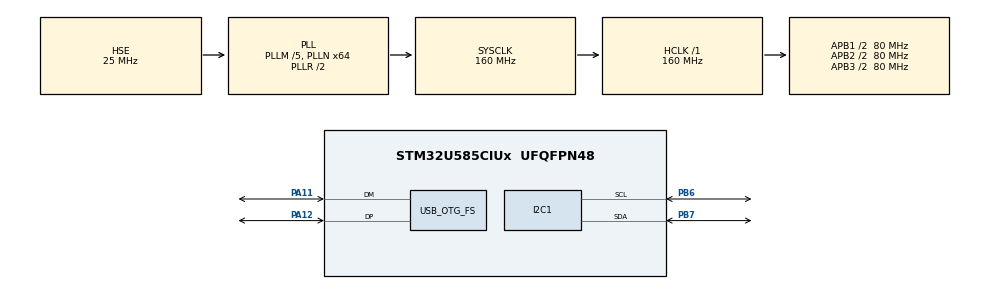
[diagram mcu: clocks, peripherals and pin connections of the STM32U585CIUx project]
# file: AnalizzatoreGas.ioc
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CORTEX_M33_NS.userName=CORTEX_M33
I2C1.Timing=0x10909CEC
Mcu.Family=STM32U5
Mcu.Name=STM32U585CIUx
Mcu.Package=UFQFPN48
NVIC.OTG_FS_IRQn=true\:0\:0\:false\:false\:true\:false\:true\:true\:true
NVIC.PriorityGroup=NVIC_PRIORITYGROUP_4
NVIC.TIM1_UP_IRQn=true\:15\:0\:false\:false\:true\:false\:false\:true\:true
NVIC.TimeBase=TIM1_UP_IRQn
NVIC.TimeBaseIP=TIM1
PA11.Mode=Device_Only
PA11.Signal=USB_OTG_FS_DM
PA12.Mode=Device_Only
PA12.Signal=USB_OTG_FS_DP
PA13\ (JTMS/SWDIO).Mode=Serial_Wire
PA13\ (JTMS/SWDIO).Signal=DEBUG_JTMS-SWDIO
PA14\ (JTCK/SWCLK).Mode=Serial_Wire
PA14\ (JTCK/SWCLK).Signal=DEBUG_JTCK-SWCLK
PB6.Mode=I2C
PB6.Signal=I2C1_SCL
PB7.Mode=I2C
PB7.Signal=I2C1_SDA
PH0-OSC_IN\ (PH0).Mode=HSE-External-Oscillator
PH0-OSC_IN\ (PH0).Signal=RCC_OSC_IN
PH1-OSC_OUT\ (PH1).Mode=HSE-External-Oscillator
PH1-OSC_OUT\ (PH1).Signal=RCC_OSC_OUT
ProjectManager.HeapSize=0x200
ProjectManager.StackSize=0x400
ProjectManager.TargetToolchain=STM32CubeIDE
RCC.ADCFreq_Value=16000000
RCC.AHBFreq_Value=160000000
RCC.APB1CLKDivider=RCC_HCLK_DIV2
RCC.APB1Freq_Value=80000000
RCC.APB1TimFreq_Value=160000000
RCC.APB2CLKDivider=RCC_HCLK_DIV2
RCC.APB2Freq_Value=80000000
RCC.APB2TimFreq_Value=160000000
RCC.APB3CLKDivider=RCC_HCLK_DIV2
RCC.APB3Freq_Value=80000000
RCC.CortexFreq_Value=160000000
RCC.EPOD_VALUE=25000000
RCC.HCLKFreq_Value=160000000
RCC.HSE_VALUE=25000000
RCC.HSI48_VALUE=48000000
RCC.HSI_VALUE=16000000
RCC.LSE_VALUE=32768
RCC.LSIDIV_VALUE=32000
RCC.MSI_VALUE=4000000
RCC.PLLM=5
RCC.PLLN=64
RCC.PLLSourceVirtual=RCC_PLLSOURCE_HSE
RCC.SYSCLKFreq_VALUE=160000000
RCC.SYSCLKSource=RCC_SYSCLKSOURCE_PLLCLK
RCC.USBFreq_Value=48000000
RCC.VCOOutputFreq_Value=320000000
THREADX.TX_APP_CREATION=1
THREADX.TX_APP_GENERATE_INIT_CODE=true
THREADX.TX_APP_MEM_POOL_SIZE=16384
THREADX.TX_APP_STACK_SIZE=4096
THREADX.TX_MINIMUM_STACK=1024
THREADX.TX_TIMER_THREAD_STACK_SIZE=2048
THREADX.TX_TIMER_TICKS_PER_SECOND=1000
USBX.Core_System=1
USBX.USBD_CDCACM_EPIN_ADDR=2
USBX.USBD_CDCACM_EPOUT_ADDR=3
USBX.USBX_DEVICE_APP_THREAD_Size=4096
USBX.USBX_DEVICE_SYS_SIZE=1024
USBX.UX_DEVICE_APP_MEM_POOL_SIZE=32768
USBX.UX_DEVICE_CDC_ACM=1
USBX.UX_Device_CoreStack=1
USB_OTG_FS.VirtualMode=Device_Only
VP_ICACHE_VS_ICACHE.Mode=DirectMappedCache
VP_LPBAMQUEUE_VS_QUEUE.Mode=QUEUEMODE
VP_LPBAM_VS_SIG1.Mode=SmartRun
VP_LPBAM_VS_SIG4.Mode=LPDMA1
VP_MEMORYMAP_VS_MEMORYMAP.Mode=CurAppReg
VP_PWR_VS_SECSignals.Mode=Security/Privilege
VP_SYS_VS_tim1.Mode=TIM1
VP_THREADX_VS_RTOSJjThreadXJjCoreJjDefault.Mode=Core_Default
VP_USBX_Core_System.Mode=Core_System
VP_USBX_UX\ Device\ CDC\ ACM\ Class_FS.Mode=UX_Device_class_CDC_ACM_FS
VP_USBX_UX\ Device\ CoreStack_FS.Mode=UX_Device_CoreStack_FS
board=custom

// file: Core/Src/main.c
/* USER CODE BEGIN Header */
/**
  ******************************************************************************
  * @file           : main.c
  * @brief          : Main program body
  ******************************************************************************
  * @attention
  *
  * Copyright (c) 2026 STMicroelectronics.
  * All rights reserved.
  *
  * This software is licensed under terms that can be found in the LICENSE file
  * in the root directory of this software component.
  * If no LICENSE file comes with this software, it is provided AS-IS.
  *
  ******************************************************************************
  */
/* USER CODE END Header */
#include "app_threadx.h"
#include "main.h"

I2C_HandleTypeDef hi2c1;

//PCD_HandleTypeDef hpcd_USB_OTG_FS;

void SystemClock_Config(void);
static void MX_GPIO_Init(void);
static void MX_ICACHE_Init(void);
static void MX_USB_OTG_FS_PCD_Init(void);
static void MX_I2C1_Init(void);

/* USER CODE BEGIN 0 */
PCD_HandleTypeDef hpcd_USB_OTG_FS;
/* USER CODE END 0 */

int main(void)
{

  /* MCU Configuration--------------------------------------------------------*/

  /* Reset of all peripherals, Initializes the Flash interface and the Systick. */
  HAL_Init();

  /* Configure the system clock */
  SystemClock_Config();

  /* Initialize all configured peripherals */
  MX_GPIO_Init();
  MX_ICACHE_Init();
  MX_USB_OTG_FS_PCD_Init();
  MX_I2C1_Init();

  MX_ThreadX_Init();

  /* We should never get here as control is now taken by the scheduler */

  /* Infinite loop */
  while (1)
  {

  }
}

void SystemClock_Config(void)
{
  RCC_OscInitTypeDef RCC_OscInitStruct = {0};
  RCC_ClkInitTypeDef RCC_ClkInitStruct = {0};

  /** Configure the main internal regulator output voltage
  */
  if (HAL_PWREx_ControlVoltageScaling(PWR_REGULATOR_VOLTAGE_SCALE1) != HAL_OK)
  {
    Error_Handler();
  }

  /** Initializes the CPU, AHB and APB buses clocks
  */
  RCC_OscInitStruct.OscillatorType = RCC_OSCILLATORTYPE_HSI48|RCC_OSCILLATORTYPE_HSE;
  RCC_OscInitStruct.HSEState = RCC_HSE_ON;
  RCC_OscInitStruct.HSI48State = RCC_HSI48_ON;
  RCC_OscInitStruct.PLL.PLLState = RCC_PLL_ON;
  RCC_OscInitStruct.PLL.PLLSource = RCC_PLLSOURCE_HSE;
  RCC_OscInitStruct.PLL.PLLMBOOST = RCC_PLLMBOOST_DIV2;
  RCC_OscInitStruct.PLL.PLLM = 5;
  RCC_OscInitStruct.PLL.PLLN = 64;
  RCC_OscInitStruct.PLL.PLLP = 2;
  RCC_OscInitStruct.PLL.PLLQ = 2;
  RCC_OscInitStruct.PLL.PLLR = 2;
  RCC_OscInitStruct.PLL.PLLRGE = RCC_PLLVCIRANGE_0;
  RCC_OscInitStruct.PLL.PLLFRACN = 0;
  if (HAL_RCC_OscConfig(&RCC_OscInitStruct) != HAL_OK)
  {
    Error_Handler();
  }

  /** Initializes the CPU, AHB and APB buses clocks
  */
  RCC_ClkInitStruct.ClockType = RCC_CLOCKTYPE_HCLK|RCC_CLOCKTYPE_SYSCLK
                              |RCC_CLOCKTYPE_PCLK1|RCC_CLOCKTYPE_PCLK2
                              |RCC_CLOCKTYPE_PCLK3;
  RCC_ClkInitStruct.SYSCLKSource = RCC_SYSCLKSOURCE_PLLCLK;
  RCC_ClkInitStruct.AHBCLKDivider = RCC_SYSCLK_DIV1;
  RCC_ClkInitStruct.APB1CLKDivider = RCC_HCLK_DIV2;
  RCC_ClkInitStruct.APB2CLKDivider = RCC_HCLK_DIV2;
  RCC_ClkInitStruct.APB3CLKDivider = RCC_HCLK_DIV2;

  if (HAL_RCC_ClockConfig(&RCC_ClkInitStruct, FLASH_LATENCY_4) != HAL_OK)
  {
    Error_Handler();
  }
}

static void MX_I2C1_Init(void)
{

  hi2c1.Instance = I2C1;
  hi2c1.Init.Timing = 0x10909CEC;
  hi2c1.Init.OwnAddress1 = 0;
  hi2c1.Init.AddressingMode = I2C_ADDRESSINGMODE_7BIT;
  hi2c1.Init.DualAddressMode = I2C_DUALADDRESS_DISABLE;
  hi2c1.Init.OwnAddress2 = 0;
  hi2c1.Init.OwnAddress2Masks = I2C_OA2_NOMASK;
  hi2c1.Init.GeneralCallMode = I2C_GENERALCALL_DISABLE;
  hi2c1.Init.NoStretchMode = I2C_NOSTRETCH_DISABLE;
  if (HAL_I2C_Init(&hi2c1) != HAL_OK)
  {
    Error_Handler();
  }

  /** Configure Analogue filter
  */
  if (HAL_I2CEx_ConfigAnalogFilter(&hi2c1, I2C_ANALOGFILTER_ENABLE) != HAL_OK)
  {
    Error_Handler();
  }

  /** Configure Digital filter
  */
  if (HAL_I2CEx_ConfigDigitalFilter(&hi2c1, 0) != HAL_OK)
  {
    Error_Handler();
  }

}

static void MX_ICACHE_Init(void)
{

  /** Enable instruction cache in 1-way (direct mapped cache)
  */
  if (HAL_ICACHE_ConfigAssociativityMode(ICACHE_1WAY) != HAL_OK)
  {
    Error_Handler();
  }
  if (HAL_ICACHE_Enable() != HAL_OK)
  {
    Error_Handler();
  }

}

static void MX_USB_OTG_FS_PCD_Init(void)
{

  hpcd_USB_OTG_FS.Instance = USB_OTG_FS;
  hpcd_USB_OTG_FS.Init.dev_endpoints = 6;
  hpcd_USB_OTG_FS.Init.speed = PCD_SPEED_FULL;
  hpcd_USB_OTG_FS.Init.phy_itface = PCD_PHY_EMBEDDED;
  hpcd_USB_OTG_FS.Init.Sof_enable = DISABLE;
  hpcd_USB_OTG_FS.Init.low_power_enable = DISABLE;
  hpcd_USB_OTG_FS.Init.lpm_enable = DISABLE;
  hpcd_USB_OTG_FS.Init.battery_charging_enable = DISABLE;
  hpcd_USB_OTG_FS.Init.use_dedicated_ep1 = DISABLE;
  hpcd_USB_OTG_FS.Init.vbus_sensing_enable = DISABLE;
  hpcd_USB_OTG_FS.Init.dma_enable = DISABLE;
  if (HAL_PCD_Init(&hpcd_USB_OTG_FS) != HAL_OK)
  {
    Error_Handler();
  }
  /* USER CODE BEGIN USB_OTG_FS_Init 2 */
  HAL_PCDEx_SetRxFiFo(&hpcd_USB_OTG_FS, 0x80);
  HAL_PCDEx_SetTxFiFo(&hpcd_USB_OTG_FS, 0, 0x40); // EP0 IN
  HAL_PCDEx_SetTxFiFo(&hpcd_USB_OTG_FS, 1, 0x40); // CDC IN
  HAL_PCDEx_SetTxFiFo(&hpcd_USB_OTG_FS, 2, 0x40); // EP2 IN (0x82)
  /* USER CODE END USB_OTG_FS_Init 2 */

}

static void MX_GPIO_Init(void)
{

  /* GPIO Ports Clock Enable */
  __HAL_RCC_GPIOH_CLK_ENABLE();
  __HAL_RCC_GPIOA_CLK_ENABLE();
  __HAL_RCC_GPIOB_CLK_ENABLE();

}

void HAL_TIM_PeriodElapsedCallback(TIM_HandleTypeDef *htim)
{
  if (htim->Instance == TIM1)
  {
    HAL_IncTick();
  }
}

void Error_Handler(void)
{
  __disable_irq();
  while (1)
  {
  }
}
